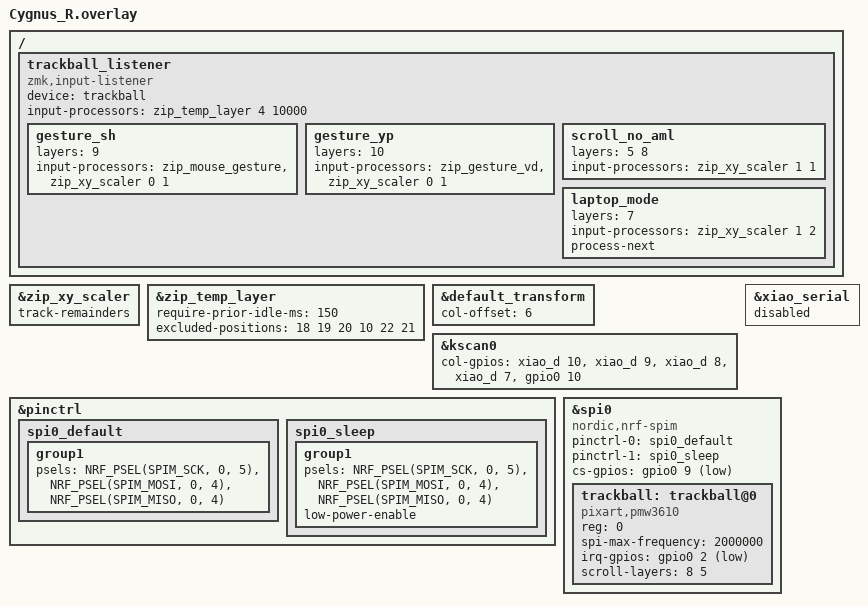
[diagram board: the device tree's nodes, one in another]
#include "Cygnus.dtsi"
#include <input/processors.dtsi>

// 追加: 移動量の間引きで端数を切り捨てず持ち越す（ゆっくり動かした時のカクつき防止）
&zip_xy_scaler {
    track-remainders;
};

// 追加(2026-09-30): Arai氏方式のAML（ZMK標準の一時レイヤー）
// ボールが止まってから10秒間レイヤー4を保つ。下の番号のキー以外を押すと即座に抜ける
&zip_temp_layer {
    require-prior-idle-ms = <150>;   // 直前150ms以内にキーを打っていたらAMLに入らない（打鍵中に親指がボールに触れた時の誤作動対策）
    // 変更(2026-09-30): 除外キーを6つに絞った。これ以外のキーは押すとAMLを抜け、レイヤー0の文字が出る
    excluded-positions = <
        18 19 20         // T N S の位置: MB1(左), MB3(中), MB2(右)クリック
        10 22            // E Z の位置: Ctrl, Shift（修飾クリック用）
        21               // H の位置: SCROLL2（AML中にホールドでスクロール）
    >;
};

&default_transform {
    col-offset = <6>;
};

&kscan0 {
        col-gpios
            = <&xiao_d 10 GPIO_ACTIVE_HIGH>
            , <&xiao_d 9 GPIO_ACTIVE_HIGH> 
            , <&xiao_d 8 GPIO_ACTIVE_HIGH> 
            , <&xiao_d 7 GPIO_ACTIVE_HIGH> 
            , <&gpio0 10 GPIO_ACTIVE_HIGH>
            ;
};

/ {
    trackball_listener {
        compatible = "zmk,input-listener";
        device = <&trackball>;
        input-processors = <&zip_temp_layer 4 10000>;   // 追加(2026-09-30): AML本体

        // 追加(2026-10-01): レイヤー9（S+Hの長押し）の間はボールをジェスチャーとして読む
        // カーソルは止める（0倍）。ここで処理を止めるのでAMLにも入らない
        gesture_sh {
            layers = <9>;
            input-processors = <&zip_mouse_gesture &zip_xy_scaler 0 1>;
        };

        // 追加(2026-10-01): レイヤー10（Y+Pの長押し）の間は2組目のジェスチャー
        gesture_yp {
            layers = <10>;
            input-processors = <&zip_gesture_vd &zip_xy_scaler 0 1>;
        };

        // 追加(2026-09-30): スクロール中（レイヤー5・8）はAMLに入らない
        // 何もしない処理（等倍）を置き、ここで処理を止めて上のAMLを通さない
        scroll_no_aml {
            layers = <5 8>;
            input-processors = <&zip_xy_scaler 1 1>;
        };

        // 追加: ノートモード（レイヤー7）がオンの間、カーソル移動を 1/2 に縮める
        // CPI 1200 x 1/2 = 600相当。数字を変えれば調整できる（例: 2 3 で800相当、1 3 で400相当）
        laptop_mode {
            layers = <7>;
            input-processors = <&zip_xy_scaler 1 2>;
            process-next;   // 追加(2026-09-30): 減速のあとAML本体にも処理を渡す（無いとノートモード中にAMLが効かない）
        };
    };
};

&pinctrl {
    spi0_default: spi0_default {
        group1 {
            psels = <NRF_PSEL(SPIM_SCK, 0, 5)>,
                <NRF_PSEL(SPIM_MOSI, 0, 4)>,
                <NRF_PSEL(SPIM_MISO, 0, 4)>;
        };
    };

    spi0_sleep: spi0_sleep {
        group1 {
            psels = <NRF_PSEL(SPIM_SCK, 0, 5)>,
                <NRF_PSEL(SPIM_MOSI, 0, 4)>,
                <NRF_PSEL(SPIM_MISO, 0, 4)>;
            low-power-enable;
        };
    };
};

&xiao_serial { status = "disabled"; };

&spi0 {
    status = "okay";
    compatible = "nordic,nrf-spim";
    pinctrl-0 = <&spi0_default>;
    pinctrl-1 = <&spi0_sleep>;
    pinctrl-names = "default", "sleep";
    cs-gpios = <&gpio0 9 GPIO_ACTIVE_LOW>;

    trackball: trackball@0 {
        status = "okay";
        compatible = "pixart,pmw3610";
        reg = <0>;
        spi-max-frequency = <2000000>;
        irq-gpios = <&gpio0 2 (GPIO_ACTIVE_LOW | GPIO_PULL_UP)>;
        // automouse-layer = <4>;   // 変更(2026-09-30): ドライバ側のAMLは停止。ZMK標準の一時レイヤーに置き換え
        scroll-layers = <8 5>;    // 変更: 8を先頭に（プログラムが最初の番号しか見ていない可能性への対策）
    };
};


